VERSION "HSCAN2"

NS_ :

BS_:

BU_: FVCM GW Diagnostics EPS SCSABS Tester

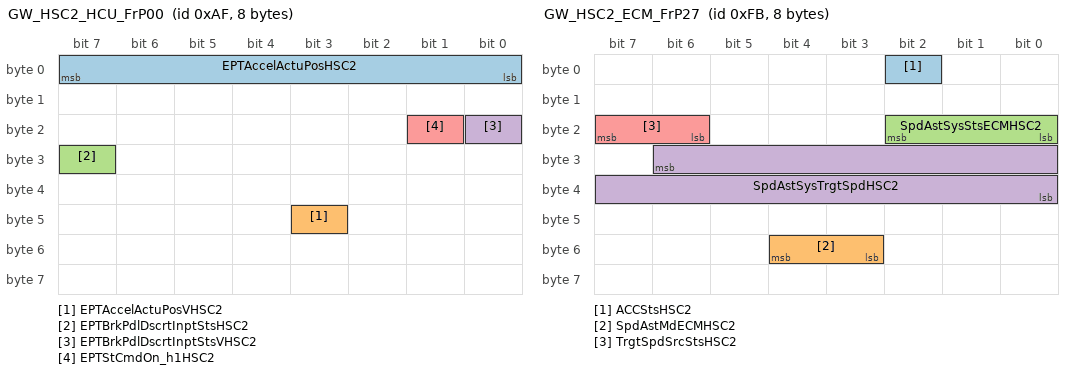
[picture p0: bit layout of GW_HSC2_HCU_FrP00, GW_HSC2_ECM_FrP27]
BO_ 175 GW_HSC2_HCU_FrP00: 8 GW
 SG_ EPTAccelActuPosHSC2 : 7|8@0+ (0.392157,0) [0|100] "%"  FVCM
 SG_ EPTAccelActuPosVHSC2 : 43|1@0+ (1,0) [0|1] ""  FVCM
 SG_ EPTBrkPdlDscrtInptStsHSC2 : 31|1@0+ (1,0) [0|1] ""  FVCM
 SG_ EPTBrkPdlDscrtInptStsVHSC2 : 16|1@0+ (1,0) [0|1] ""  FVCM
 SG_ EPTStCmdOn_h1HSC2 : 17|1@0+ (1,0) [0|1] ""  FVCM

BO_ 251 GW_HSC2_ECM_FrP27: 8 GW
 SG_ ACCStsHSC2 : 2|1@0+ (1,0) [0|1] "" XXX
 SG_ SpdAstMdECMHSC2 : 52|2@0+ (1,0) [0|3] ""  FVCM
 SG_ SpdAstSysStsECMHSC2 : 18|3@0+ (1,0) [0|7] ""  FVCM
 SG_ SpdAstSysTrgtSpdHSC2 : 30|15@0+ (0.015625,0) [0|511.984] ""  FVCM
 SG_ TrgtSpdSrcStsHSC2 : 23|2@0+ (1,0) [0|3] ""  FVCM

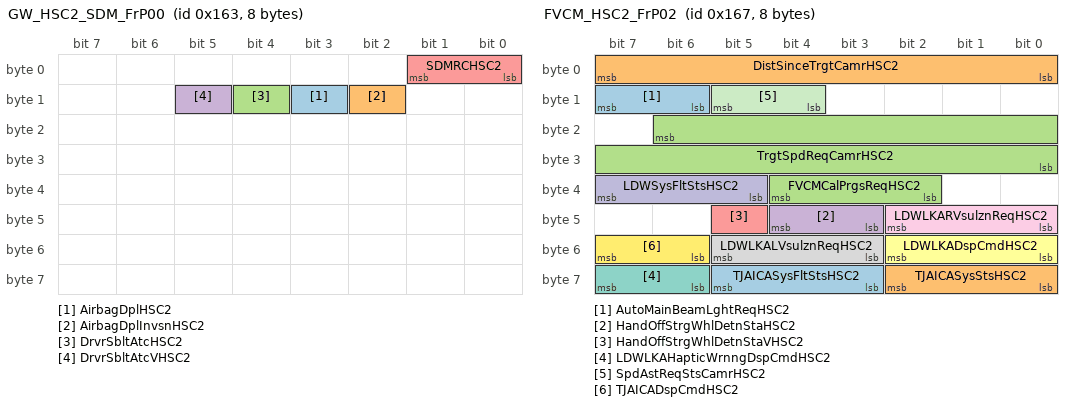
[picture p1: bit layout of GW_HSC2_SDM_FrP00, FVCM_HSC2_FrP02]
BO_ 355 GW_HSC2_SDM_FrP00: 8 GW
 SG_ AirbagDplHSC2 : 11|1@0+ (1,0) [0|1] ""  FVCM
 SG_ AirbagDplInvsnHSC2 : 10|1@0+ (1,0) [0|1] ""  FVCM
 SG_ DrvrSbltAtcHSC2 : 12|1@0+ (1,0) [0|1] ""  FVCM
 SG_ DrvrSbltAtcVHSC2 : 13|1@0+ (1,0) [0|1] ""  FVCM
 SG_ SDMRCHSC2 : 1|2@0+ (1,0) [0|3] ""  FVCM

BO_ 359 FVCM_HSC2_FrP02: 8 FVCM
 SG_ AutoMainBeamLghtReqHSC2 : 15|2@0+ (1,0) [0|3] ""  GW
 SG_ DistSinceTrgtCamrHSC2 : 7|8@0+ (8.235,-100) [-100|1999.92] "m"  GW
 SG_ FVCMCalPrgsReqHSC2 : 36|3@0+ (1,0) [0|7] ""  GW
 SG_ HandOffStrgWhlDetnStaHSC2 : 44|2@0+ (1,0) [0|3] ""  GW
 SG_ HandOffStrgWhlDetnStaVHSC2 : 45|1@0+ (1,0) [0|1] ""  GW
 SG_ LDWLKADspCmdHSC2 : 50|3@0+ (1,0) [0|7] ""  GW
 SG_ LDWLKAHapticWrnngDspCmdHSC2 : 63|2@0+ (1,0) [0|3] ""  GW
 SG_ LDWLKALVsulznReqHSC2 : 53|3@0+ (1,0) [0|7] ""  GW
 SG_ LDWLKARVsulznReqHSC2 : 42|3@0+ (1,0) [0|7] ""  GW
 SG_ LDWSysFltStsHSC2 : 39|3@0+ (1,0) [0|7] ""  GW
 SG_ SpdAstReqStsCamrHSC2 : 13|2@0+ (1,0) [0|3] ""  GW
 SG_ TJAICADspCmdHSC2 : 55|2@0+ (1,0) [0|3] ""  GW
 SG_ TJAICASysFltStsHSC2 : 61|3@0+ (1,0) [0|7] ""  GW,EPS
 SG_ TJAICASysStsHSC2 : 58|3@0+ (1,0) [0|7] ""  GW,EPS
 SG_ TrgtSpdReqCamrHSC2 : 22|15@0+ (0.015625,0) [0|511.984] ""  GW

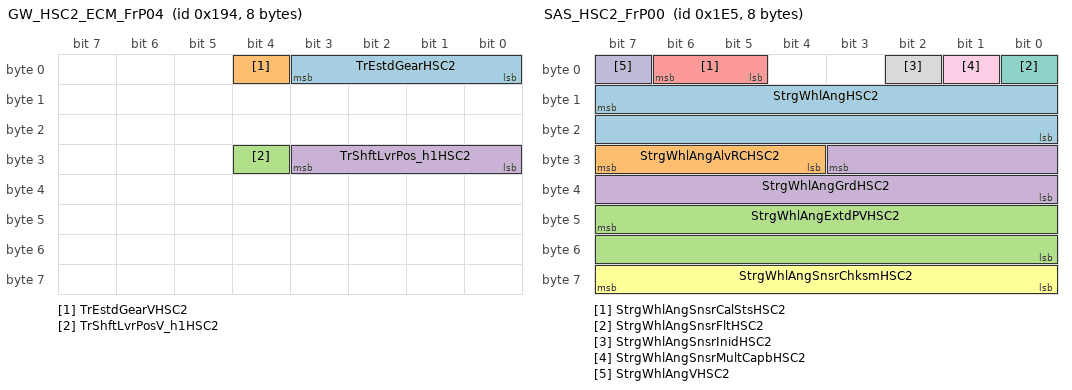
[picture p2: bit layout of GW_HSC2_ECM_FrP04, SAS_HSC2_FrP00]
BO_ 404 GW_HSC2_ECM_FrP04: 8 GW
 SG_ TrEstdGearHSC2 : 3|4@0+ (1,0) [0|15] ""  FVCM
 SG_ TrEstdGearVHSC2 : 4|1@0+ (1,0) [0|1] ""  FVCM
 SG_ TrShftLvrPosV_h1HSC2 : 28|1@0+ (1,0) [0|1] ""  FVCM
 SG_ TrShftLvrPos_h1HSC2 : 27|4@0+ (1,0) [0|15] ""  FVCM

BO_ 485 SAS_HSC2_FrP00: 8 EPS
 SG_ StrgWhlAngHSC2 : 15|16@0+ (0.0625,-2048) [-2048|2047.88] "degree"  FVCM
 SG_ StrgWhlAngAlvRCHSC2 : 31|4@0+ (1,0) [0|15] ""  FVCM
 SG_ StrgWhlAngExtdPVHSC2 : 47|16@0+ (1,0) [0|65535] ""  FVCM
 SG_ StrgWhlAngGrdHSC2 : 27|12@0+ (1,-2048) [-2048|2046] "degree/s"  FVCM
 SG_ StrgWhlAngSnsrCalStsHSC2 : 6|2@0+ (1,0) [0|3] ""  FVCM
 SG_ StrgWhlAngSnsrChksmHSC2 : 63|8@0+ (1,0) [0|255] ""  FVCM
 SG_ StrgWhlAngSnsrFltHSC2 : 0|1@0+ (1,0) [0|1] ""  FVCM
 SG_ StrgWhlAngSnsrInidHSC2 : 2|1@0+ (1,0) [0|1] ""  FVCM
 SG_ StrgWhlAngSnsrMultCapbHSC2 : 1|1@0+ (1,0) [0|1] ""  FVCM
 SG_ StrgWhlAngVHSC2 : 7|1@0+ (1,0) [0|1] ""  FVCM

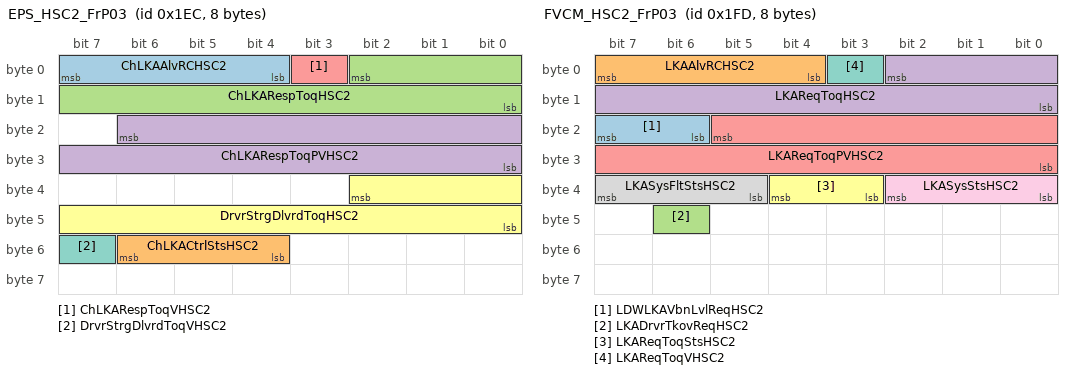
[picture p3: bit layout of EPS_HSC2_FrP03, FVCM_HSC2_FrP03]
BO_ 492 EPS_HSC2_FrP03: 8 EPS
 SG_ ChLKAAlvRCHSC2 : 7|4@0+ (1,0) [0|15] ""  FVCM
 SG_ ChLKACtrlStsHSC2 : 54|3@0+ (1,0) [0|7] ""  FVCM
 SG_ ChLKARespToqHSC2 : 2|11@0+ (0.01,-10.24) [-10.24|10.23] "Nm"  FVCM
 SG_ ChLKARespToqPVHSC2 : 22|15@0+ (1,0) [0|32767] ""  FVCM
 SG_ ChLKARespToqVHSC2 : 3|1@0+ (1,0) [0|1] ""  FVCM
 SG_ DrvrStrgDlvrdToqHSC2 : 34|11@0+ (0.01,-10.24) [-10.24|10.23] "Nm"  FVCM
 SG_ DrvrStrgDlvrdToqVHSC2 : 55|1@0+ (1,0) [0|1] ""  FVCM

BO_ 509 FVCM_HSC2_FrP03: 8 FVCM
 SG_ LDWLKAVbnLvlReqHSC2 : 23|2@0+ (1,0) [0|3] ""  GW,EPS
 SG_ LKAAlvRCHSC2 : 7|4@0+ (1,0) [0|15] ""  EPS
 SG_ LKADrvrTkovReqHSC2 : 46|1@0+ (1,0) [0|1] ""  GW,EPS
 SG_ LKAReqToqHSC2 : 2|11@0+ (0.01,-10.24) [-10.24|10.23] "Nm"  EPS
 SG_ LKAReqToqPVHSC2 : 21|14@0+ (1,0) [0|16383] ""  EPS
 SG_ LKAReqToqStsHSC2 : 36|2@0+ (1,0) [0|3] ""  EPS
 SG_ LKAReqToqVHSC2 : 3|1@0+ (1,0) [0|1] ""  EPS
 SG_ LKASysFltStsHSC2 : 39|3@0+ (1,0) [0|7] ""  GW,EPS
 SG_ LKASysStsHSC2 : 34|3@0+ (1,0) [0|7] ""  GW,EPS

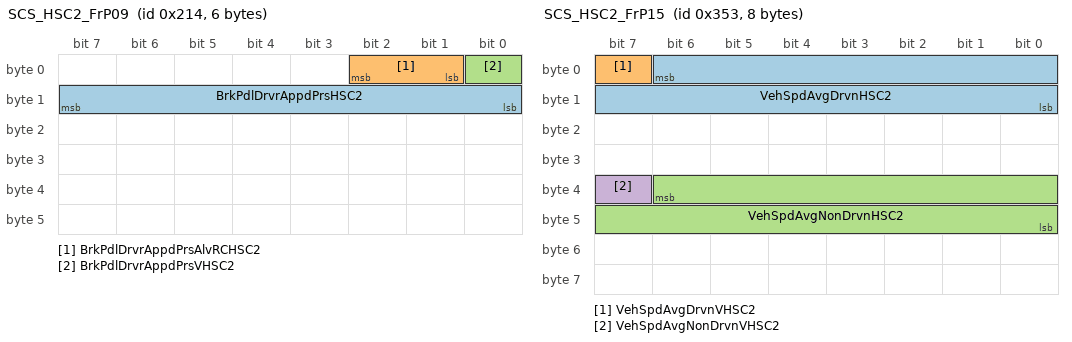
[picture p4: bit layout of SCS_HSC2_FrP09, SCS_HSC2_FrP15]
BO_ 532 SCS_HSC2_FrP09: 6 SCSABS
 SG_ BrkPdlDrvrAppdPrsHSC2 : 15|8@0+ (75,0) [0|19125] "kPa"  FVCM
 SG_ BrkPdlDrvrAppdPrsAlvRCHSC2 : 2|2@0+ (1,0) [0|3] ""  FVCM
 SG_ BrkPdlDrvrAppdPrsVHSC2 : 0|1@0+ (1,0) [0|1] ""  FVCM

BO_ 851 SCS_HSC2_FrP15: 8 SCSABS
 SG_ VehSpdAvgDrvnHSC2 : 6|15@0+ (0.015625,0) [0|511.984] "km/h"  FVCM
 SG_ VehSpdAvgDrvnVHSC2 : 7|1@0+ (1,0) [0|1] ""  FVCM
 SG_ VehSpdAvgNonDrvnHSC2 : 38|15@0+ (0.015625,0) [0|511.984] "km/h"  FVCM
 SG_ VehSpdAvgNonDrvnVHSC2 : 39|1@0+ (1,0) [0|1] ""  FVCM

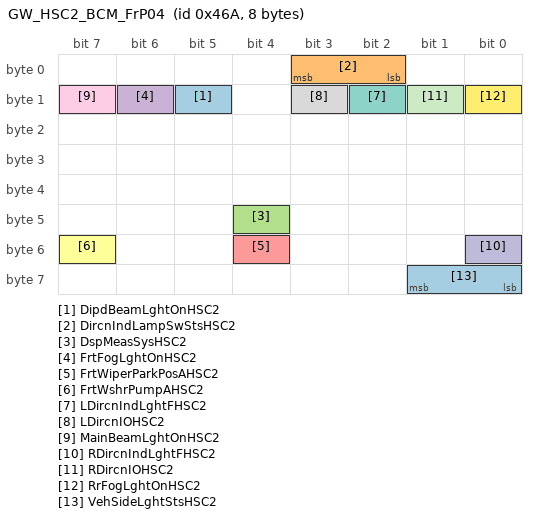
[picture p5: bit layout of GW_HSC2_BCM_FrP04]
BO_ 1130 GW_HSC2_BCM_FrP04: 8 GW
 SG_ DipdBeamLghtOnHSC2 : 13|1@0+ (1,0) [0|1] ""  FVCM
 SG_ DircnIndLampSwStsHSC2 : 3|2@0+ (1,0) [0|3] ""  FVCM
 SG_ DspMeasSysHSC2 : 44|1@0+ (1,0) [0|1] ""  FVCM
 SG_ FrtFogLghtOnHSC2 : 14|1@0+ (1,0) [0|1] ""  FVCM
 SG_ FrtWiperParkPosAHSC2 : 52|1@0+ (1,0) [0|1] ""  FVCM
 SG_ FrtWshrPumpAHSC2 : 55|1@0+ (1,0) [0|1] ""  FVCM
 SG_ LDircnIndLghtFHSC2 : 10|1@0+ (1,0) [0|1] ""  FVCM
 SG_ LDircnIOHSC2 : 11|1@0+ (1,0) [0|1] ""  FVCM
 SG_ MainBeamLghtOnHSC2 : 15|1@0+ (1,0) [0|1] ""  FVCM
 SG_ RDircnIndLghtFHSC2 : 48|1@0+ (1,0) [0|1] ""  FVCM
 SG_ RDircnIOHSC2 : 9|1@0+ (1,0) [0|1] ""  FVCM
 SG_ RrFogLghtOnHSC2 : 8|1@0+ (1,0) [0|1] ""  FVCM
 SG_ VehSideLghtStsHSC2 : 57|2@0+ (1,0) [0|3] ""  FVCM

VAL_ 355 AirbagDplInvsnHSC2 1 "No Airbag Deployed" 0 "Airbag Deployed";
VAL_ 355 AirbagDplHSC2 1 "True" 0 "False";
VAL_ 355 DrvrSbltAtcHSC2 1 "True" 0 "False";
VAL_ 355 DrvrSbltAtcVHSC2 1 "Invalid" 0 "Valid";
VAL_ 404 TrEstdGearHSC2 15 "Park Gear" 14 "Reverse Gear" 13 "Neutral Gear" 8 "Eighth Gear" 7 "Seventh Gear" 6 "Sixth Gear" 5 "Fifth Gear" 4 "Fourth Gear" 3 "Third Gear" 2 "Second Gear" 1 "First Gear" 0 "Not Supported";
VAL_ 404 TrEstdGearVHSC2 1 "Invalid" 0 "Valid";
VAL_ 404 TrShftLvrPos_h1HSC2 15 "Lever Position Unknown" 11 "Forward Range H" 10 "Forward Range G" 9 "Forward Range F" 8 "Forward Range E" 7 "Forward Range D" 6 "Forward Range C" 5 "Forward Range B" 4 "Forward Range A" 3 "Neutral Range" 2 "Reverse Range" 1 "Park Range" 0 "Between Ranges";
VAL_ 404 TrShftLvrPosV_h1HSC2 1 "Invalid" 0 "Valid";
VAL_ 509 LKAReqToqVHSC2 1 "Invalid" 0 "Valid";
VAL_ 509 LDWLKAVbnLvlReqHSC2 3 "Level 3" 2 "Level 2" 1 "Level 1" 0 "no request";
VAL_ 509 LKASysStsHSC2 3 "Override" 2 "Active" 1 "Stand by" 0 "Off";
VAL_ 509 LKAReqToqStsHSC2 3 "reserved" 2 "reserved" 1 "torque request" 0 "no request";
VAL_ 509 LKASysFltStsHSC2 3 "service required" 2 "system temporary unavailable" 1 "performance degradation" 0 "no error";
VAL_ 509 LKADrvrTkovReqHSC2 1 "True" 0 "False";
